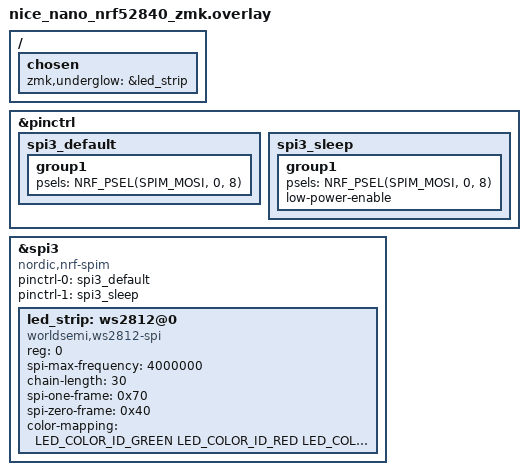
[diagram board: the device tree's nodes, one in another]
#include <dt-bindings/led/led.h>

/*
 * This PCB (Sofle Choc Wireless, github.com/db-ok/SofleChocWireless) relocates
 * the per-key RGB data line to P0.08 (Arduino D0) to free up P0.06 (D1) for
 * the nice!view CS pin, instead of the P0.06 the stock sofle+nice_nano/zmk
 * overlay assumes.
 */
&pinctrl {
    spi3_default: spi3_default {
        group1 {
            psels = <NRF_PSEL(SPIM_MOSI, 0, 8)>;
        };
    };

    spi3_sleep: spi3_sleep {
        group1 {
            psels = <NRF_PSEL(SPIM_MOSI, 0, 8)>;
            low-power-enable;
        };
    };
};

&spi3 {
    compatible = "nordic,nrf-spim";
    status = "okay";

    pinctrl-0 = <&spi3_default>;
    pinctrl-1 = <&spi3_sleep>;
    pinctrl-names = "default", "sleep";

    led_strip: ws2812@0 {
        compatible = "worldsemi,ws2812-spi";

        /* SPI */
        reg = <0>; /* ignored, but necessary for SPI bindings */
        spi-max-frequency = <4000000>;

        /* WS2812 */
        chain-length = <30>; /* Sofle Choc Wireless: 60 SK6812 MINI-E LEDs total, 30 per half */
        spi-one-frame = <0x70>;
        spi-zero-frame = <0x40>;

        color-mapping = <
            LED_COLOR_ID_GREEN
            LED_COLOR_ID_RED
            LED_COLOR_ID_BLUE
        >;
    };
};

/ {
    chosen {
        zmk,underglow = &led_strip;
    };
};
